# ATmega16HVBrevB device description
Architecture: AVR8; Family: megaAVR
Registers are 8-bit, access not given, no defined reset value unless marked. A register's access mark holds for its fields unless they carry their own. Offsets are from the block's base; [hi:lo] are bit positions.

## LOCKBIT — Lockbits
Instances: LOCKBIT 0 in lockbits
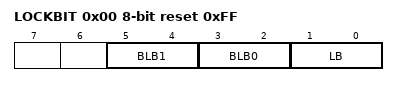
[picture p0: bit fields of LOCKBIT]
0x00 LOCKBIT reset 0xFF
  [5:4] BLB1 — Boot Loader Protection Mode
    0=LPM_SPM_DISABLE (LPM and SPM prohibited in Boot Section); 1=LPM_DISABLE (LPM prohibited in Boot Section); 2=SPM_DISABLE (SPM prohibited in Boot Section); 3=NO_LOCK (No lock on SPM and LPM in Boot Section)
  [3:2] BLB0 — Boot Loader Protection Mode
    0=LPM_SPM_DISABLE (LPM and SPM prohibited in Application Section); 1=LPM_DISABLE (LPM prohibited in Application Section); 2=SPM_DISABLE (SPM prohibited in Application Section); 3=NO_LOCK (No lock on SPM and LPM in Application Section)
  [1:0] LB — Memory Lock
    0=PROG_VER_DISABLED (Further programming and verification disabled); 2=PROG_DISABLED (Further programming disabled); 3=NO_LOCK (No memory lock features enabled)

## ADC — Analog-to-Digital Converter
Instances: ADC 0x00
0x78 VADC 16-bit — VADC Data Register Bytes
  [11:0] VADC — VADC Data bits
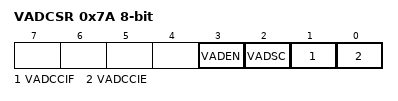
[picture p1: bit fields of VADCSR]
0x7A VADCSR — The VADC Control and Status register
  [3] VADEN — VADC Enable
  [2] VADSC — VADC Satrt Conversion
  [1] VADCCIF — VADC Conversion Complete Interrupt Flag
  [0] VADCCIE — VADC Conversion Complete Interrupt Enable
0x7C VADMUX — The VADC multiplexer Selection Register
  [3:0] VADMUX — Analog Channel and Gain Selection Bits

## WDT — Watchdog Timer
Instances: WDT 0x00
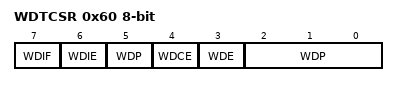
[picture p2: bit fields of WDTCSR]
0x60 WDTCSR — Watchdog Timer Control Register
  [7] WDIF — Watchdog Timeout Interrupt Flag
  [6] WDIE — Watchdog Timeout Interrupt Enable
  [4] WDCE — Watchdog Change Enable
  [3] WDE — Watch Dog Enable
  [5,2:0] WDP — Watchdog Timer Prescaler Bits
    0=Oscillator Cycles 2K; 1=Oscillator Cycles 4K; 2=Oscillator Cycles 8K; 3=Oscillator Cycles 16K; 4=Oscillator Cycles 32K; 5=Oscillator Cycles 64K; 6=Oscillator Cycles 128K; 7=Oscillator Cycles 256K; 8=Oscillator Cycles 512K; 9=Oscillator Cycles 1024K

## FET — FET Control
Instances: FET 0x00
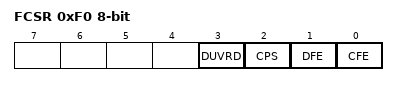
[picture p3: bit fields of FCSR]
0xF0 FCSR — FET Control and Status Register
  [3] DUVRD — Deep Under-Voltage Recovery Disable
  [2] CPS — Current Protection Status
  [1] DFE — Discharge FET Enable
  [0] CFE — Charge FET Enable

## SPI — Serial Peripheral Interface
Instances: SPI 0x00
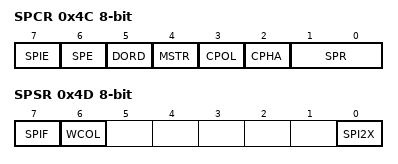
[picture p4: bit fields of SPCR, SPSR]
0x4C SPCR — SPI Control Register
  [7] SPIE — SPI Interrupt Enable
  [6] SPE — SPI Enable
  [5] DORD — Data Order
  [4] MSTR — Master/Slave Select
  [3] CPOL — Clock polarity
  [2] CPHA — Clock Phase
  [1:0] SPR — SPI Clock Rate Selects
    0=fosc/4; 1=fosc/16; 2=fosc/64; 3=fosc/128; 4=fosc/2; 5=fosc/8; 6=fosc/32; 7=fosc/64
0x4D SPSR — SPI Status Register
  [7] SPIF — SPI Interrupt Flag
  [6] WCOL — Write Collision Flag
  [0] SPI2X — Double SPI Speed Bit
0x4E SPDR — SPI Data Register
  [7:0] SPDR — SPI Data bits

## EEPROM
Instances: EEPROM 0x00
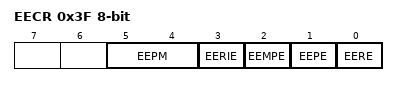
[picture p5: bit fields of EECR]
0x3F EECR — EEPROM Control Register
  [5:4] EEPM
    0=Erase and Write in one operation; 1=Erase Only; 2=Write Only
  [3] EERIE — EEProm Ready Interrupt Enable
  [2] EEMPE — EEPROM Master Write Enable
  [1] EEPE — EEPROM Write Enable
  [0] EERE — EEPROM Read Enable
0x40 EEDR — EEPROM Data Register
  [7:0] EEDR — EEPROM Data bits
0x41 EEAR 16-bit — EEPROM Read/Write Access
  [9:0] EEAR — EEPROM Address bits

## COULOMB_COUNTER
Instances: COULOMB_COUNTER 0x00
0xE0 CADAC0 — ADC Accumulate Current
  [7:0] CADAC0 — ADC accumulate current bits
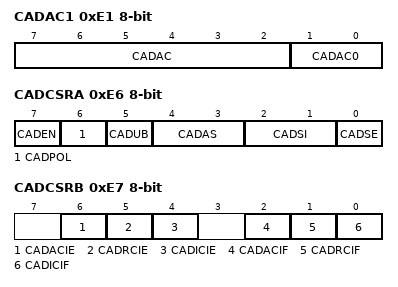
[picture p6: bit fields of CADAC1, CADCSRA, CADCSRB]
0xE1 CADAC1 — ADC Accumulate Current
  [7:2] CADAC (bit 10 of the value upward) — ADC accumulate current bits
  [1:0] CADAC0 (bit 8 of the value upward) — ADC accumulate current bits
0xE2 CADAC2 — ADC Accumulate Current
  [7:0] CADAC (bit 16 of the value upward) — ADC accumulate current bits
0xE3 CADAC3 — ADC Accumulate Current
  [7:0] CADAC (bit 24 of the value upward) — ADC accumulate current bits
0xE4 CADIC 16-bit — CC-ADC Instantaneous Current
0xE6 CADCSRA — CC-ADC Control and Status Register A
  [7] CADEN — When the CADEN bit is cleared (zero), the CC-ADC is disabled. When the CADEN bit is set (one), the CC-ADC will continuously measure the voltage drop over the external sense resistor RSENSE. In Power-down, only the Regular Current detection is active. In Power-off, the CC-ADC is always disabled.
  [6] CADPOL
  [5] CADUB — CC_ADC Update Busy
  [4:3] CADAS — CC_ADC Accumulate Current Select Bits
  [2:1] CADSI — The CADSI bits determine the current sampling interval for the Regular Current detection in Power-down mode. The actual settings remain to be determined.
  [0] CADSE — When the CADSE bit is written to one, the ongoing CC-ADC conversion is aborted, and the CC-ADC enters Regular Current detection mode.
0xE7 CADCSRB — CC-ADC Control and Status Register B
  [6] CADACIE
  [5] CADRCIE — Regular Current Interrupt Enable
  [4] CADICIE — CAD Instantenous Current Interrupt Enable
  [2] CADACIF — CC-ADC Accumulate Current Interrupt Flag
  [1] CADRCIF — CC-ADC Accumulate Current Interrupt Flag
  [0] CADICIF — CC-ADC Instantaneous Current Interrupt Flag
0xE8 CADCSRC — CC-ADC Control and Status Register C
  [0] CADVSE — CC-ADC Voltage Scaling Enable
0xE9 CADRCC — CC-ADC Regular Charge Current
0xEA CADRDC — CC-ADC Regular Discharge Current
